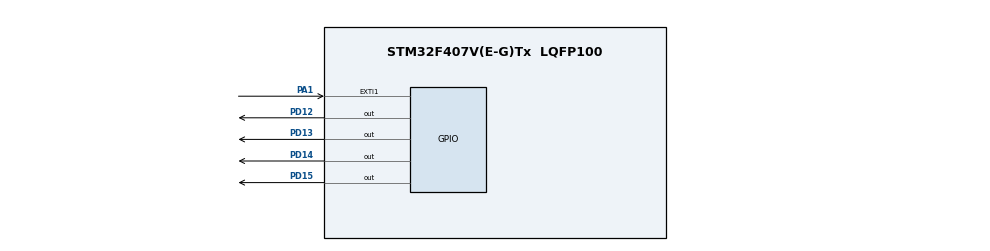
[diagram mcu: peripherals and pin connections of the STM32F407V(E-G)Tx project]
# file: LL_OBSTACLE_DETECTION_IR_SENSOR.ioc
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Mcu.Family=STM32F4
Mcu.Name=STM32F407V(E-G)Tx
Mcu.Package=LQFP100
NVIC.EXTI1_IRQn=true\:0\:0\:false\:false\:true\:true\:true\:true
NVIC.PriorityGroup=NVIC_PRIORITYGROUP_4
PA1.GPIO_ModeDefaultEXTI=GPIO_MODE_IT_RISING_FALLING
PA1.Signal=GPXTI1
PD12.GPIO_Speed=GPIO_SPEED_FREQ_VERY_HIGH
PD12.Signal=GPIO_Output
PD13.GPIO_Speed=GPIO_SPEED_FREQ_VERY_HIGH
PD13.Signal=GPIO_Output
PD14.GPIO_Speed=GPIO_SPEED_FREQ_VERY_HIGH
PD14.Signal=GPIO_Output
PD15.GPIO_Speed=GPIO_SPEED_FREQ_VERY_HIGH
PD15.Signal=GPIO_Output
PH0-OSC_IN.Mode=HSE-External-Oscillator
PH0-OSC_IN.Signal=RCC_OSC_IN
PH1-OSC_OUT.Mode=HSE-External-Oscillator
PH1-OSC_OUT.Signal=RCC_OSC_OUT
ProjectManager.HeapSize=0x200
ProjectManager.StackSize=0x400
ProjectManager.TargetToolchain=STM32CubeIDE
RCC.48MHZClocksFreq_Value=84000000
RCC.AHBFreq_Value=168000000
RCC.APB1CLKDivider=RCC_HCLK_DIV4
RCC.APB1Freq_Value=42000000
RCC.APB1TimFreq_Value=84000000
RCC.APB2CLKDivider=RCC_HCLK_DIV2
RCC.APB2Freq_Value=84000000
RCC.APB2TimFreq_Value=168000000
RCC.CortexFreq_Value=168000000
RCC.HCLKFreq_Value=168000000
RCC.HSE_VALUE=8000000
RCC.HSI_VALUE=16000000
RCC.LSE_VALUE=32768
RCC.PLLM=4
RCC.PLLN=168
RCC.PLLSourceVirtual=RCC_PLLSOURCE_HSE
RCC.SYSCLKFreq_VALUE=168000000
RCC.SYSCLKSource=RCC_SYSCLKSOURCE_PLLCLK
RCC.VCOOutputFreq_Value=336000000
board=custom

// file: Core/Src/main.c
/* USER CODE BEGIN Header */
/**
  ******************************************************************************
  * @file           : main.c
  * @brief          : Main program body
  ******************************************************************************
  * @attention
  *
  * Copyright (c) 2024 STMicroelectronics.
  * All rights reserved.
  *
  * This software is licensed under terms that can be found in the LICENSE file
  * in the root directory of this software component.
  * If no LICENSE file comes with this software, it is provided AS-IS.
  *
  ******************************************************************************
  */
/* USER CODE END Header */
#include "main.h"

void SystemClock_Config(void);
static void MX_GPIO_Init(void);

/* USER CODE BEGIN 0 */
void EXTI1_IRQHandler(void)
{
  /* USER CODE BEGIN EXTI1_IRQn 0 */
  // This section is used to handle EXTI line 1 interrupts
  /* USER CODE END EXTI1_IRQn 0 */
  if (LL_EXTI_IsActiveFlag_0_31(LL_EXTI_LINE_1) != RESET)
  {
    LL_EXTI_ClearFlag_0_31(LL_EXTI_LINE_1);
    /* USER CODE BEGIN LL_EXTI_LINE_1 */
    // Check the state of GPIOA pin 1
    if(LL_GPIO_IsInputPinSet(GPIOA, LL_GPIO_PIN_1))
    {
      // If GPIOA pin 1 is HIGH, reset (turn off) the LEDs connected to GPIOD
      LL_GPIO_ResetOutputPin(GPIOD, LL_GPIO_PIN_12 | LL_GPIO_PIN_13 | LL_GPIO_PIN_14 | LL_GPIO_PIN_15);
    }
    else
    {
      // If GPIOA pin 1 is LOW, set (turn on) the LEDs connected to GPIOD
      LL_GPIO_SetOutputPin(GPIOD, LL_GPIO_PIN_12 | LL_GPIO_PIN_13 | LL_GPIO_PIN_14 | LL_GPIO_PIN_15 );
    }
    /* USER CODE END LL_EXTI_LINE_1 */
  }
  /* USER CODE BEGIN EXTI1_IRQn 1 */

  /* USER CODE END EXTI1_IRQn 1 */
}
/* USER CODE END 0 */

int main(void)
{

  /* MCU Configuration--------------------------------------------------------*/

  /* Reset of all peripherals, Initializes the Flash interface and the Systick. */
  LL_APB2_GRP1_EnableClock(LL_APB2_GRP1_PERIPH_SYSCFG);
  LL_APB1_GRP1_EnableClock(LL_APB1_GRP1_PERIPH_PWR);

  /* System interrupt init*/
  NVIC_SetPriorityGrouping(NVIC_PRIORITYGROUP_4);

  /* SysTick_IRQn interrupt configuration */
  NVIC_SetPriority(SysTick_IRQn, NVIC_EncodePriority(NVIC_GetPriorityGrouping(),15, 0));

  /* Configure the system clock */
  SystemClock_Config();

  /* Initialize all configured peripherals */
  MX_GPIO_Init();
  /* USER CODE BEGIN 2 */
  // Enable EXTI line 1 interrupt
  LL_EXTI_EnableIT_0_31(LL_EXTI_LINE_1);
  /* USER CODE END 2 */

  /* Infinite loop */
  while (1)
  {

  }
}

void SystemClock_Config(void)
{
  // Configure the flash latency to 5 wait states
  LL_FLASH_SetLatency(LL_FLASH_LATENCY_5);
  while(LL_FLASH_GetLatency()!= LL_FLASH_LATENCY_5)
  {
  }
  // Set the voltage scaling to the lowest setting
  LL_PWR_SetRegulVoltageScaling(LL_PWR_REGU_VOLTAGE_SCALE1);
  LL_RCC_HSE_Enable();

   /* Wait till HSE is ready */
  while(LL_RCC_HSE_IsReady() != 1)
  {

  }
  // Configure the PLL to use HSE, set multipliers and dividers
  LL_RCC_PLL_ConfigDomain_SYS(LL_RCC_PLLSOURCE_HSE, LL_RCC_PLLM_DIV_4, 168, LL_RCC_PLLP_DIV_2);
  LL_RCC_PLL_Enable();

   /* Wait till PLL is ready */
  while(LL_RCC_PLL_IsReady() != 1)
  {

  }
  while (LL_PWR_IsActiveFlag_VOS() == 0)
  {
  }
  // Configure the AHB, APB1, and APB2 prescalers
  LL_RCC_SetAHBPrescaler(LL_RCC_SYSCLK_DIV_1);
  LL_RCC_SetAPB1Prescaler(LL_RCC_APB1_DIV_4);
  LL_RCC_SetAPB2Prescaler(LL_RCC_APB2_DIV_2);
  // Select the PLL as the system clock source
  LL_RCC_SetSysClkSource(LL_RCC_SYS_CLKSOURCE_PLL);

   /* Wait till System clock is ready */
  while(LL_RCC_GetSysClkSource() != LL_RCC_SYS_CLKSOURCE_STATUS_PLL)
  {

  }
  // Initialize the 1ms tick
  LL_Init1msTick(168000000);
  // Set the system core clock
  LL_SetSystemCoreClock(168000000);
}

static void MX_GPIO_Init(void)
{
  LL_EXTI_InitTypeDef EXTI_InitStruct = {0};
  LL_GPIO_InitTypeDef GPIO_InitStruct = {0};

  /* GPIO Ports Clock Enable */
  LL_AHB1_GRP1_EnableClock(LL_AHB1_GRP1_PERIPH_GPIOH);
  LL_AHB1_GRP1_EnableClock(LL_AHB1_GRP1_PERIPH_GPIOA);
  LL_AHB1_GRP1_EnableClock(LL_AHB1_GRP1_PERIPH_GPIOD);

  // Initialize GPIOD pins (LEDs) to be LOW
  LL_GPIO_ResetOutputPin(GPIOD, LL_GPIO_PIN_12|LL_GPIO_PIN_13|LL_GPIO_PIN_14|LL_GPIO_PIN_15);

  // Configure EXTI line 1 source to be GPIOA
  LL_SYSCFG_SetEXTISource(LL_SYSCFG_EXTI_PORTA, LL_SYSCFG_EXTI_LINE1);

  // Configure EXTI line 1 settings
  EXTI_InitStruct.Line_0_31 = LL_EXTI_LINE_1;
  EXTI_InitStruct.LineCommand = ENABLE;
  EXTI_InitStruct.Mode = LL_EXTI_MODE_IT;
  EXTI_InitStruct.Trigger = LL_EXTI_TRIGGER_RISING_FALLING;
  LL_EXTI_Init(&EXTI_InitStruct);

  // Configure GPIOA pin 1 settings (input mode, no pull-up/pull-down)
  LL_GPIO_SetPinPull(GPIOA, LL_GPIO_PIN_1, LL_GPIO_PULL_NO);
  LL_GPIO_SetPinMode(GPIOA, LL_GPIO_PIN_1, LL_GPIO_MODE_INPUT);

  // Configure GPIOD pins (LEDs) settings
  GPIO_InitStruct.Pin = LL_GPIO_PIN_12|LL_GPIO_PIN_13|LL_GPIO_PIN_14|LL_GPIO_PIN_15;
  GPIO_InitStruct.Mode = LL_GPIO_MODE_OUTPUT;
  GPIO_InitStruct.Speed = LL_GPIO_SPEED_FREQ_VERY_HIGH;
  GPIO_InitStruct.OutputType = LL_GPIO_OUTPUT_PUSHPULL;
  GPIO_InitStruct.Pull = LL_GPIO_PULL_NO;
  LL_GPIO_Init(GPIOD, &GPIO_InitStruct);

  /* EXTI interrupt init*/
  // Configure NVIC for EXTI line 1 interrupts
  NVIC_SetPriority(EXTI1_IRQn, NVIC_EncodePriority(NVIC_GetPriorityGrouping(),0, 0));
  NVIC_EnableIRQ(EXTI1_IRQn);

}

void Error_Handler(void)
{
  /* USER CODE BEGIN Error_Handler_Debug */
  // User can add his own implementation to report the HAL error return state
  __disable_irq();
  while (1)
  {
  }
  /* USER CODE END Error_Handler_Debug */
}

#ifdef  USE_FULL_ASSERT
/**
  * @brief  Reports the name of the source file and the source line number
  *         where the assert_param error has occurred.
  * @param  file: pointer to the source file name
  * @param  line: assert_param error line source number
  * @retval None
  */
void assert_failed(uint8_t *file, uint32_t line)
{
  /* USER CODE BEGIN 6 */
  // User can add his own implementation to report the file name and line number
  /* USER CODE END 6 */
}
#endif /* USE_FULL_ASSERT */
